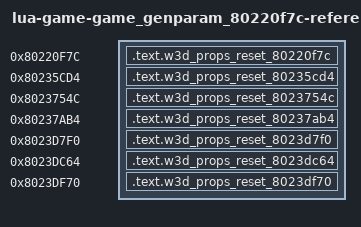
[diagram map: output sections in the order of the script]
/* Generated reference-only placements. All bodies are source-built. */
OUTPUT_FORMAT("elf32-powerpc")
OUTPUT_ARCH(powerpc)
ENTRY(w3d_props_reset_80220f7c)
_SDA_BASE_ = 0x804b2540;
_SDA2_BASE_ = 0x804c2540;
fn_801e8d9c = 0x801e8d9c;
fn_801ed24c = 0x801ed24c;
fn_8020bb2c = 0x8020bb2c;
fn_8020c5c0 = 0x8020c5c0;
fn_8020c5c4 = 0x8020c5c4;
fn_80341588 = 0x80341588;
fn_80341884 = 0x80341884;
lbl_803b67a4 = 0x803b67a4;
lbl_803b67d8 = 0x803b67d8;
lbl_803bab44 = 0x803bab44;
lbl_803bab70 = 0x803bab70;
lbl_803bb050 = 0x803bb050;
lbl_803bb07c = 0x803bb07c;
lbl_803bb0bc = 0x803bb0bc;
lbl_803bb0e0 = 0x803bb0e0;
lbl_803bc420 = 0x803bc420;
lbl_803bc44c = 0x803bc44c;
lbl_803bc48c = 0x803bc48c;
lbl_803bc4b0 = 0x803bc4b0;
lbl_803bc4e4 = 0x803bc4e4;
lbl_803bc508 = 0x803bc508;
lbl_804b06a0 = 0x804b06a0;
SECTIONS {
  .text.w3d_props_reset_80220f7c 0x80220f7c : { *(.text.w3d_props_reset_80220f7c) }
  .text.w3d_props_reset_80235cd4 0x80235cd4 : { *(.text.w3d_props_reset_80235cd4) }
  .text.w3d_props_reset_8023754c 0x8023754c : { *(.text.w3d_props_reset_8023754c) }
  .text.w3d_props_reset_80237ab4 0x80237ab4 : { *(.text.w3d_props_reset_80237ab4) }
  .text.w3d_props_reset_8023d7f0 0x8023d7f0 : { *(.text.w3d_props_reset_8023d7f0) }
  .text.w3d_props_reset_8023dc64 0x8023dc64 : { *(.text.w3d_props_reset_8023dc64) }
  .text.w3d_props_reset_8023df70 0x8023df70 : { *(.text.w3d_props_reset_8023df70) }
  /DISCARD/ : { *(.text*) *(.rodata*) *(.data*) *(.bss*) *(.sdata*) *(.sbss*) *(.comment) }
}
